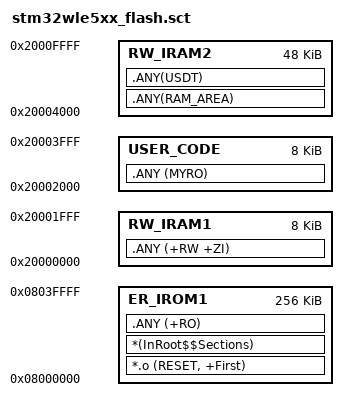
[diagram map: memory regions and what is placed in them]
; *************************************************************
; *** Scatter-Loading Description File generated by uVision ***
; *************************************************************

LR_IROM1 0x08000000 0x00040000  {    ; load region size_region
  ; FLASH for kernel
  ER_IROM1 0x08000000 0x00040000  {  ; load address = execution address
   *.o (RESET, +First)
   *(InRoot$$Sections)
   .ANY (+RO)
  }
  ; Non-backup SRAM1
  RW_IRAM1 0x20000000 0x00002000  {  ; RW data
   .ANY (+RW +ZI)
  }
  USER_CODE 0x20002000 0x00002000 {
   .ANY (MYRO)
  }
  ; Backup SRAM2
  RW_IRAM2 0x20004000 0x0000C000{
	.ANY(RAM_AREA)
	.ANY(USDT)
	
  }
}
